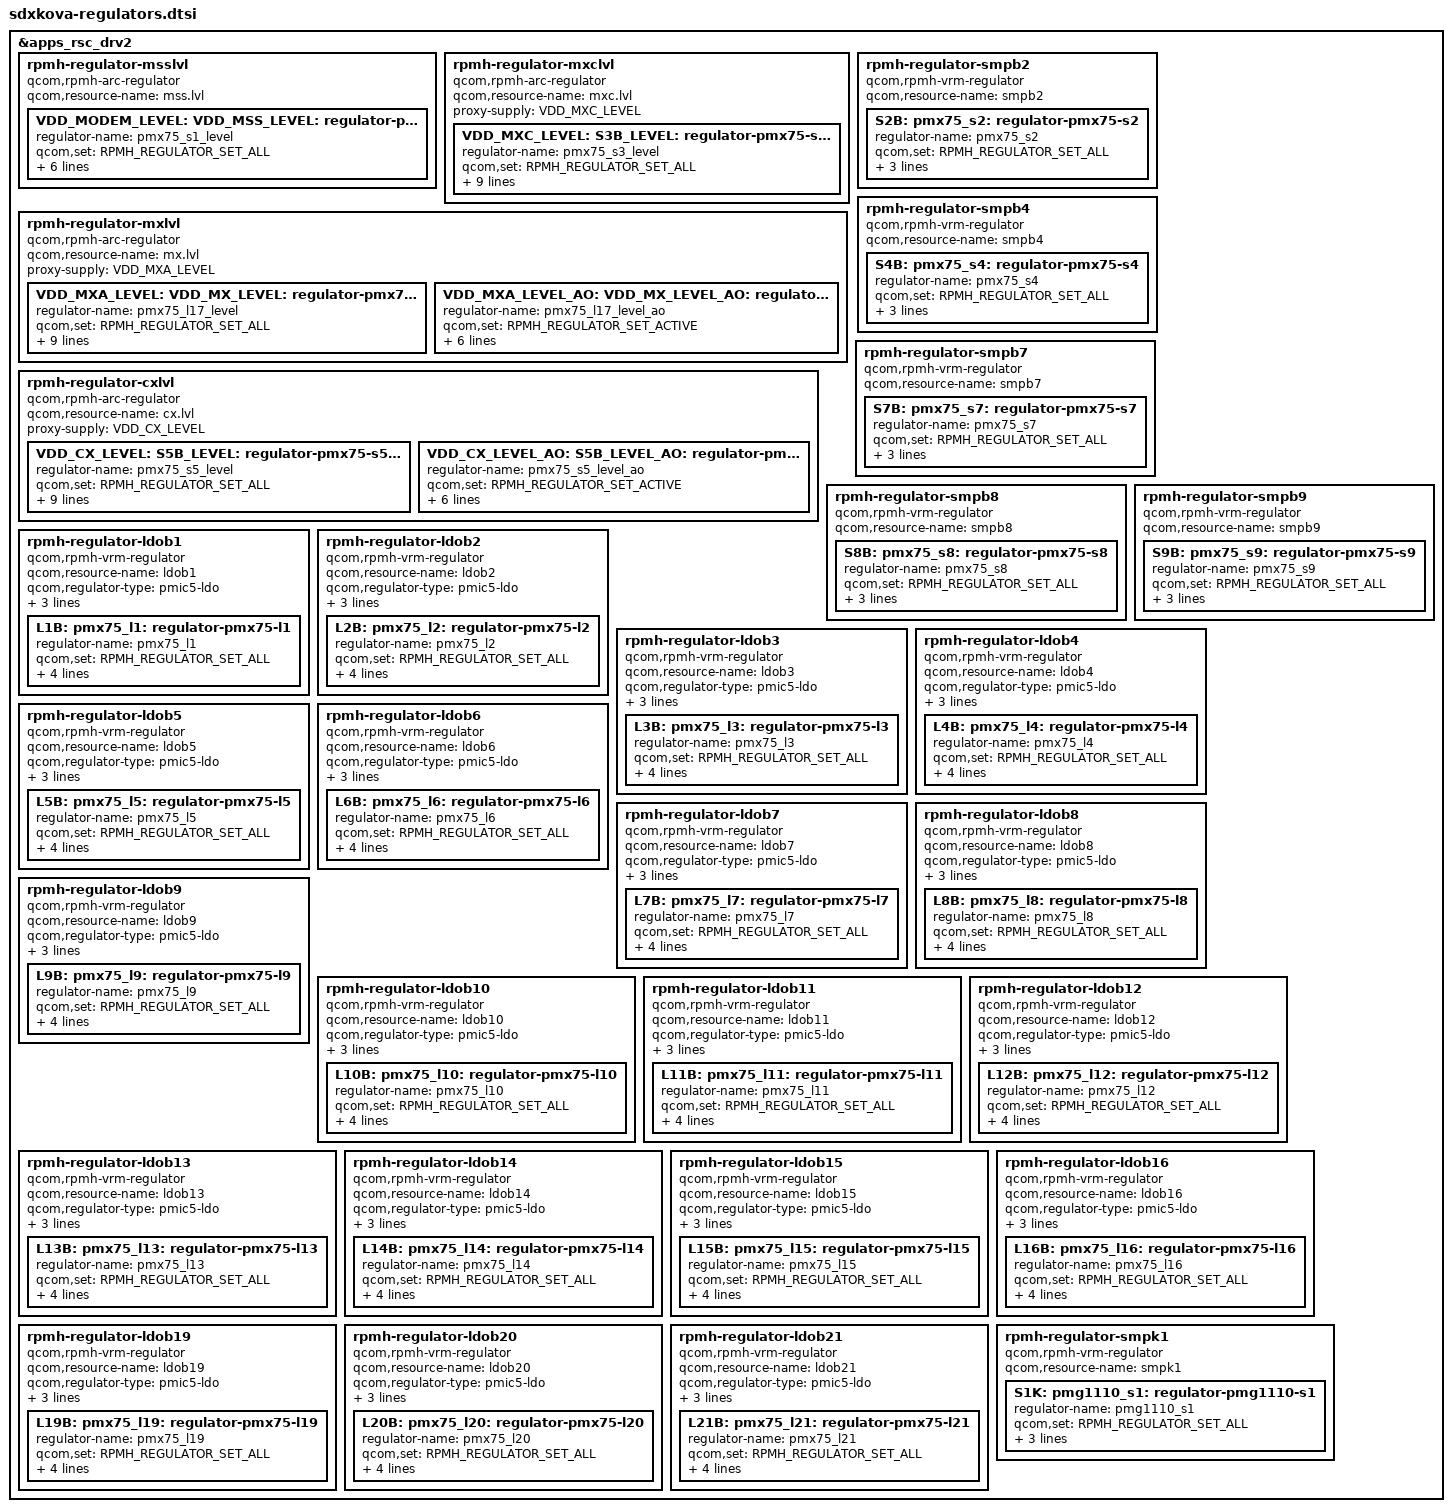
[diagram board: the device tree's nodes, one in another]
// SPDX-License-Identifier: BSD-3-Clause
/*
 * Copyright (c) 2024 Qualcomm Innovation Center, Inc. All rights reserved.
 */

#include <dt-bindings/regulator/qcom,rpmh-regulator-levels.h>

&apps_rsc_drv2 {
	rpmh-regulator-msslvl {
		compatible = "qcom,rpmh-arc-regulator";
		qcom,resource-name = "mss.lvl";

		VDD_MODEM_LEVEL: VDD_MSS_LEVEL: S1B_LEVEL:
		pmx75_s1_level: regulator-pmx75-s1-level {
			regulator-name = "pmx75_s1_level";
			qcom,set = <RPMH_REGULATOR_SET_ALL>;
			regulator-min-microvolt =
				<RPMH_REGULATOR_LEVEL_RETENTION>;
			regulator-max-microvolt =
				<RPMH_REGULATOR_LEVEL_MAX>;
			qcom,init-voltage-level =
				<RPMH_REGULATOR_LEVEL_RETENTION>;
		};
	};

	rpmh-regulator-mxclvl {
		compatible = "qcom,rpmh-arc-regulator";
		qcom,resource-name = "mxc.lvl";
		proxy-supply = <&VDD_MXC_LEVEL>;

		VDD_MXC_LEVEL: S3B_LEVEL:
		pmx75_s3_level: regulator-pmx75-s3-level {
			regulator-name = "pmx75_s3_level";
			qcom,set = <RPMH_REGULATOR_SET_ALL>;
			regulator-min-microvolt =
				<RPMH_REGULATOR_LEVEL_RETENTION>;
			regulator-max-microvolt =
				<RPMH_REGULATOR_LEVEL_MAX>;
			qcom,init-voltage-level =
				<RPMH_REGULATOR_LEVEL_TURBO>;
			qcom,proxy-consumer-enable;
			qcom,proxy-consumer-voltage =
				<RPMH_REGULATOR_LEVEL_TURBO
				RPMH_REGULATOR_LEVEL_MAX>;
		};
	};

	rpmh-regulator-mxlvl {
		compatible = "qcom,rpmh-arc-regulator";
		qcom,resource-name = "mx.lvl";
		proxy-supply = <&VDD_MXA_LEVEL>;

		VDD_MXA_LEVEL: VDD_MX_LEVEL: L17B_LEVEL:
		pmx75_l17_level: regulator-pmx75-l17-level {
			regulator-name = "pmx75_l17_level";
			qcom,set = <RPMH_REGULATOR_SET_ALL>;
			regulator-min-microvolt =
				<RPMH_REGULATOR_LEVEL_RETENTION>;
			regulator-max-microvolt =
				<RPMH_REGULATOR_LEVEL_MAX>;
			qcom,init-voltage-level =
				<RPMH_REGULATOR_LEVEL_TURBO>;
			qcom,proxy-consumer-enable;
			qcom,proxy-consumer-voltage =
				<RPMH_REGULATOR_LEVEL_TURBO
				RPMH_REGULATOR_LEVEL_MAX>;
		};

		VDD_MXA_LEVEL_AO: VDD_MX_LEVEL_AO: L17B_LEVEL_AO:
		pmx75_l17_level_ao: regulator-pmx75-l17-level-ao {
			regulator-name = "pmx75_l17_level_ao";
			qcom,set = <RPMH_REGULATOR_SET_ACTIVE>;
			regulator-min-microvolt =
				<RPMH_REGULATOR_LEVEL_RETENTION>;
			regulator-max-microvolt =
				<RPMH_REGULATOR_LEVEL_MAX>;
			qcom,init-voltage-level =
				<RPMH_REGULATOR_LEVEL_RETENTION>;
		};
	};

	rpmh-regulator-cxlvl {
		compatible = "qcom,rpmh-arc-regulator";
		qcom,resource-name = "cx.lvl";
		proxy-supply = <&VDD_CX_LEVEL>;

		VDD_CX_LEVEL: S5B_LEVEL:
		pmx75_s5_level: regulator-pmx75-s5-level {
			regulator-name = "pmx75_s5_level";
			qcom,set = <RPMH_REGULATOR_SET_ALL>;
			regulator-min-microvolt =
				<RPMH_REGULATOR_LEVEL_RETENTION>;
			regulator-max-microvolt =
				<RPMH_REGULATOR_LEVEL_MAX>;
			qcom,init-voltage-level =
				<RPMH_REGULATOR_LEVEL_TURBO>;
			qcom,proxy-consumer-enable;
			qcom,proxy-consumer-voltage =
				<RPMH_REGULATOR_LEVEL_TURBO
				 RPMH_REGULATOR_LEVEL_MAX>;
		};

		VDD_CX_LEVEL_AO: S5B_LEVEL_AO:
		pmx75_s5_level_ao: regulator-pmx75-s5-level-ao {
			regulator-name = "pmx75_s5_level_ao";
			qcom,set = <RPMH_REGULATOR_SET_ACTIVE>;
			regulator-min-microvolt =
				<RPMH_REGULATOR_LEVEL_RETENTION>;
			regulator-max-microvolt =
				<RPMH_REGULATOR_LEVEL_MAX>;
			qcom,init-voltage-level =
				<RPMH_REGULATOR_LEVEL_RETENTION>;
		};
	};

	rpmh-regulator-smpb2 {
		compatible = "qcom,rpmh-vrm-regulator";
		qcom,resource-name = "smpb2";

		S2B: pmx75_s2: regulator-pmx75-s2 {
			regulator-name = "pmx75_s2";
			qcom,set = <RPMH_REGULATOR_SET_ALL>;
			regulator-min-microvolt = <1224000>;
			regulator-max-microvolt = <1350000>;
			qcom,init-voltage = <1224000>;
		};
	};

	rpmh-regulator-smpb4 {
		compatible = "qcom,rpmh-vrm-regulator";
		qcom,resource-name = "smpb4";

		S4B: pmx75_s4: regulator-pmx75-s4 {
			regulator-name = "pmx75_s4";
			qcom,set = <RPMH_REGULATOR_SET_ALL>;
			regulator-min-microvolt = <1824000>;
			regulator-max-microvolt = <1904000>;
			qcom,init-voltage = <1824000>;
		};
	};

	rpmh-regulator-smpb7 {
		compatible = "qcom,rpmh-vrm-regulator";
		qcom,resource-name = "smpb7";

		S7B: pmx75_s7: regulator-pmx75-s7 {
			regulator-name = "pmx75_s7";
			qcom,set = <RPMH_REGULATOR_SET_ALL>;
			regulator-min-microvolt = <352000>;
			regulator-max-microvolt = <1060000>;
			qcom,init-voltage = <936000>;
		};
	};

	rpmh-regulator-smpb8 {
		compatible = "qcom,rpmh-vrm-regulator";
		qcom,resource-name = "smpb8";

		S8B: pmx75_s8: regulator-pmx75-s8 {
			regulator-name = "pmx75_s8";
			qcom,set = <RPMH_REGULATOR_SET_ALL>;
			regulator-min-microvolt = <500000>;
			regulator-max-microvolt = <1100000>;
			qcom,init-voltage = <824000>;
		};
	};

	rpmh-regulator-smpb9 {
		compatible = "qcom,rpmh-vrm-regulator";
		qcom,resource-name = "smpb9";

		S9B: pmx75_s9: regulator-pmx75-s9 {
			regulator-name = "pmx75_s9";
			qcom,set = <RPMH_REGULATOR_SET_ALL>;
			regulator-min-microvolt = <300000>;
			regulator-max-microvolt = <1040000>;
			qcom,init-voltage = <800000>;
		};
	};

	rpmh-regulator-ldob1 {
		compatible = "qcom,rpmh-vrm-regulator";
		qcom,resource-name = "ldob1";
		qcom,regulator-type = "pmic5-ldo";
		qcom,supported-modes =
			<RPMH_REGULATOR_MODE_LPM
			 RPMH_REGULATOR_MODE_HPM>;
		qcom,mode-threshold-currents = <0 30000>;

		L1B: pmx75_l1: regulator-pmx75-l1 {
			regulator-name = "pmx75_l1";
			qcom,set = <RPMH_REGULATOR_SET_ALL>;
			regulator-min-microvolt = <1200000>;
			regulator-max-microvolt = <1200000>;
			qcom,init-voltage = <1200000>;
			qcom,init-mode = <RPMH_REGULATOR_MODE_HPM>;
		};
	};

	rpmh-regulator-ldob2 {
		compatible = "qcom,rpmh-vrm-regulator";
		qcom,resource-name = "ldob2";
		qcom,regulator-type = "pmic5-ldo";
		qcom,supported-modes =
			<RPMH_REGULATOR_MODE_LPM
			 RPMH_REGULATOR_MODE_HPM>;
		qcom,mode-threshold-currents = <0 30000>;

		L2B: pmx75_l2: regulator-pmx75-l2 {
			regulator-name = "pmx75_l2";
			qcom,set = <RPMH_REGULATOR_SET_ALL>;
			regulator-min-microvolt = <1000000>;
			regulator-max-microvolt = <1160000>;
			qcom,init-voltage = <1128000>;
			qcom,init-mode = <RPMH_REGULATOR_MODE_HPM>;
		};
	};

	rpmh-regulator-ldob3 {
		compatible = "qcom,rpmh-vrm-regulator";
		qcom,resource-name = "ldob3";
		qcom,regulator-type = "pmic5-ldo";
		qcom,supported-modes =
			<RPMH_REGULATOR_MODE_LPM
			 RPMH_REGULATOR_MODE_HPM>;
		qcom,mode-threshold-currents = <0 30000>;

		L3B: pmx75_l3: regulator-pmx75-l3 {
			regulator-name = "pmx75_l3";
			qcom,set = <RPMH_REGULATOR_SET_ALL>;
			regulator-min-microvolt = <300000>;
			regulator-max-microvolt = <1040000>;
			qcom,init-voltage = <896000>;
			qcom,init-mode = <RPMH_REGULATOR_MODE_HPM>;
		};
	};

	rpmh-regulator-ldob4 {
		compatible = "qcom,rpmh-vrm-regulator";
		qcom,resource-name = "ldob4";
		qcom,regulator-type = "pmic5-ldo";
		qcom,supported-modes =
			<RPMH_REGULATOR_MODE_LPM
			 RPMH_REGULATOR_MODE_HPM>;
		qcom,mode-threshold-currents = <0 30000>;

		L4B: pmx75_l4: regulator-pmx75-l4 {
			regulator-name = "pmx75_l4";
			qcom,set = <RPMH_REGULATOR_SET_ALL>;
			regulator-min-microvolt = <864000>;
			regulator-max-microvolt = <912000>;
			qcom,init-voltage = <880000>;
			qcom,init-mode = <RPMH_REGULATOR_MODE_HPM>;
		};
	};

	rpmh-regulator-ldob5 {
		compatible = "qcom,rpmh-vrm-regulator";
		qcom,resource-name = "ldob5";
		qcom,regulator-type = "pmic5-ldo";
		qcom,supported-modes =
			<RPMH_REGULATOR_MODE_LPM
			 RPMH_REGULATOR_MODE_HPM>;
		qcom,mode-threshold-currents = <0 10000>;

		L5B: pmx75_l5: regulator-pmx75-l5 {
			regulator-name = "pmx75_l5";
			qcom,set = <RPMH_REGULATOR_SET_ALL>;
			regulator-min-microvolt = <1770000>;
			regulator-max-microvolt = <1800000>;
			qcom,init-voltage = <1776000>;
			qcom,init-mode = <RPMH_REGULATOR_MODE_HPM>;
		};
	};

	rpmh-regulator-ldob6 {
		compatible = "qcom,rpmh-vrm-regulator";
		qcom,resource-name = "ldob6";
		qcom,regulator-type = "pmic5-ldo";
		qcom,supported-modes =
			<RPMH_REGULATOR_MODE_LPM
			 RPMH_REGULATOR_MODE_HPM>;
		qcom,mode-threshold-currents = <0 10000>;

		L6B: pmx75_l6: regulator-pmx75-l6 {
			regulator-name = "pmx75_l6";
			qcom,set = <RPMH_REGULATOR_SET_ALL>;
			regulator-min-microvolt = <1800000>;
			regulator-max-microvolt = <1800000>;
			qcom,init-voltage = <1800000>;
			qcom,init-mode = <RPMH_REGULATOR_MODE_HPM>;
		};
	};

	rpmh-regulator-ldob7 {
		compatible = "qcom,rpmh-vrm-regulator";
		qcom,resource-name = "ldob7";
		qcom,regulator-type = "pmic5-ldo";
		qcom,supported-modes =
			<RPMH_REGULATOR_MODE_LPM
			 RPMH_REGULATOR_MODE_HPM>;
		qcom,mode-threshold-currents = <0 30000>;

		L7B: pmx75_l7: regulator-pmx75-l7 {
			regulator-name = "pmx75_l7";
			qcom,set = <RPMH_REGULATOR_SET_ALL>;
			regulator-min-microvolt = <300000>;
			regulator-max-microvolt = <960000>;
			qcom,init-voltage = <904000>;
			qcom,init-mode = <RPMH_REGULATOR_MODE_HPM>;
		};
	};

	rpmh-regulator-ldob8 {
		compatible = "qcom,rpmh-vrm-regulator";
		qcom,resource-name = "ldob8";
		qcom,regulator-type = "pmic5-ldo";
		qcom,supported-modes =
			<RPMH_REGULATOR_MODE_LPM
			 RPMH_REGULATOR_MODE_HPM>;
		qcom,mode-threshold-currents = <0 30000>;

		L8B: pmx75_l8: regulator-pmx75-l8 {
			regulator-name = "pmx75_l8";
			qcom,set = <RPMH_REGULATOR_SET_ALL>;
			regulator-min-microvolt = <800000>;
			regulator-max-microvolt = <800000>;
			qcom,init-voltage = <800000>;
			qcom,init-mode = <RPMH_REGULATOR_MODE_HPM>;
		};
	};

	rpmh-regulator-ldob9 {
		compatible = "qcom,rpmh-vrm-regulator";
		qcom,resource-name = "ldob9";
		qcom,regulator-type = "pmic5-ldo";
		qcom,supported-modes =
			<RPMH_REGULATOR_MODE_LPM
			 RPMH_REGULATOR_MODE_HPM>;
		qcom,mode-threshold-currents = <0 30000>;

		L9B: pmx75_l9: regulator-pmx75-l9 {
			regulator-name = "pmx75_l9";
			qcom,set = <RPMH_REGULATOR_SET_ALL>;
			regulator-min-microvolt = <752000>;
			regulator-max-microvolt = <800000>;
			qcom,init-voltage = <752000>;
			qcom,init-mode = <RPMH_REGULATOR_MODE_HPM>;
		};
	};

	rpmh-regulator-ldob10 {
		compatible = "qcom,rpmh-vrm-regulator";
		qcom,resource-name = "ldob10";
		qcom,regulator-type = "pmic5-ldo";
		qcom,supported-modes =
			<RPMH_REGULATOR_MODE_LPM
			 RPMH_REGULATOR_MODE_HPM>;
		qcom,mode-threshold-currents = <0 10000>;

		L10B: pmx75_l10: regulator-pmx75-l10 {
			regulator-name = "pmx75_l10";
			qcom,set = <RPMH_REGULATOR_SET_ALL>;
			regulator-min-microvolt = <3008000>;
			regulator-max-microvolt = <3088000>;
			qcom,init-voltage = <3080000>;
			qcom,init-mode = <RPMH_REGULATOR_MODE_HPM>;
		};
	};

	rpmh-regulator-ldob11 {
		compatible = "qcom,rpmh-vrm-regulator";
		qcom,resource-name = "ldob11";
		qcom,regulator-type = "pmic5-ldo";
		qcom,supported-modes =
			<RPMH_REGULATOR_MODE_LPM
			 RPMH_REGULATOR_MODE_HPM>;
		qcom,mode-threshold-currents = <0 10000>;

		L11B: pmx75_l11: regulator-pmx75-l11 {
			regulator-name = "pmx75_l11";
			qcom,set = <RPMH_REGULATOR_SET_ALL>;
			regulator-min-microvolt = <1704000>;
			regulator-max-microvolt = <2928000>;
			qcom,init-voltage = <1800000>;
			qcom,init-mode = <RPMH_REGULATOR_MODE_HPM>;
		};
	};

	rpmh-regulator-ldob12 {
		compatible = "qcom,rpmh-vrm-regulator";
		qcom,resource-name = "ldob12";
		qcom,regulator-type = "pmic5-ldo";
		qcom,supported-modes =
			<RPMH_REGULATOR_MODE_LPM
			 RPMH_REGULATOR_MODE_HPM>;
		qcom,mode-threshold-currents = <0 30000>;

		L12B: pmx75_l12: regulator-pmx75-l12 {
			regulator-name = "pmx75_l12";
			qcom,set = <RPMH_REGULATOR_SET_ALL>;
			regulator-min-microvolt = <1200000>;
			regulator-max-microvolt = <1200000>;
			qcom,init-voltage = <1200000>;
			qcom,init-mode = <RPMH_REGULATOR_MODE_HPM>;
		};
	};

	rpmh-regulator-ldob13 {
		compatible = "qcom,rpmh-vrm-regulator";
		qcom,resource-name = "ldob13";
		qcom,regulator-type = "pmic5-ldo";
		qcom,supported-modes =
			<RPMH_REGULATOR_MODE_LPM
			 RPMH_REGULATOR_MODE_HPM>;
		qcom,mode-threshold-currents = <0 10000>;

		L13B: pmx75_l13: regulator-pmx75-l13 {
			regulator-name = "pmx75_l13";
			qcom,set = <RPMH_REGULATOR_SET_ALL>;
			regulator-min-microvolt = <1704000>;
			regulator-max-microvolt = <2928000>;
			qcom,init-voltage = <1800000>;
			qcom,init-mode = <RPMH_REGULATOR_MODE_HPM>;
		};
	};

	rpmh-regulator-ldob14 {
		compatible = "qcom,rpmh-vrm-regulator";
		qcom,resource-name = "ldob14";
		qcom,regulator-type = "pmic5-ldo";
		qcom,supported-modes =
			<RPMH_REGULATOR_MODE_LPM
			 RPMH_REGULATOR_MODE_HPM>;
		qcom,mode-threshold-currents = <0 30000>;

		L14B: pmx75_l14: regulator-pmx75-l14 {
			regulator-name = "pmx75_l14";
			qcom,set = <RPMH_REGULATOR_SET_ALL>;
			regulator-min-microvolt = <300000>;
			regulator-max-microvolt = <800000>;
			qcom,init-voltage = <624000>;
			qcom,init-mode = <RPMH_REGULATOR_MODE_HPM>;
		};
	};

	rpmh-regulator-ldob15 {
		compatible = "qcom,rpmh-vrm-regulator";
		qcom,resource-name = "ldob15";
		qcom,regulator-type = "pmic5-ldo";
		qcom,supported-modes =
			<RPMH_REGULATOR_MODE_LPM
			 RPMH_REGULATOR_MODE_HPM>;
		qcom,mode-threshold-currents = <0 30000>;

		L15B: pmx75_l15: regulator-pmx75-l15 {
			regulator-name = "pmx75_l15";
			qcom,set = <RPMH_REGULATOR_SET_ALL>;
			regulator-min-microvolt = <1200000>;
			regulator-max-microvolt = <1200000>;
			qcom,init-voltage = <1200000>;
			qcom,init-mode = <RPMH_REGULATOR_MODE_HPM>;
		};
	};

	rpmh-regulator-ldob16 {
		compatible = "qcom,rpmh-vrm-regulator";
		qcom,resource-name = "ldob16";
		qcom,regulator-type = "pmic5-ldo";
		qcom,supported-modes =
			<RPMH_REGULATOR_MODE_LPM
			 RPMH_REGULATOR_MODE_HPM>;
		qcom,mode-threshold-currents = <0 30000>;

		L16B: pmx75_l16: regulator-pmx75-l16 {
			regulator-name = "pmx75_l16";
			qcom,set = <RPMH_REGULATOR_SET_ALL>;
			regulator-min-microvolt = <880000>;
			regulator-max-microvolt = <920000>;
			qcom,init-voltage = <912000>;
			qcom,init-mode = <RPMH_REGULATOR_MODE_HPM>;
		};
	};

	rpmh-regulator-ldob19 {
		compatible = "qcom,rpmh-vrm-regulator";
		qcom,resource-name = "ldob19";
		qcom,regulator-type = "pmic5-ldo";
		qcom,supported-modes =
			<RPMH_REGULATOR_MODE_LPM
			 RPMH_REGULATOR_MODE_HPM>;
		qcom,mode-threshold-currents = <0 30000>;

		L19B: pmx75_l19: regulator-pmx75-l19 {
			regulator-name = "pmx75_l19";
			qcom,set = <RPMH_REGULATOR_SET_ALL>;
			regulator-min-microvolt = <900000>;
			regulator-max-microvolt = <960000>;
			qcom,init-voltage = <952000>;
			qcom,init-mode = <RPMH_REGULATOR_MODE_HPM>;
		};
	};

	rpmh-regulator-ldob20 {
		compatible = "qcom,rpmh-vrm-regulator";
		qcom,resource-name = "ldob20";
		qcom,regulator-type = "pmic5-ldo";
		qcom,supported-modes =
			<RPMH_REGULATOR_MODE_LPM
			 RPMH_REGULATOR_MODE_HPM>;
		qcom,mode-threshold-currents = <0 30000>;

		L20B: pmx75_l20: regulator-pmx75-l20 {
			regulator-name = "pmx75_l20";
			qcom,set = <RPMH_REGULATOR_SET_ALL>;
			regulator-min-microvolt = <912000>;
			regulator-max-microvolt = <952000>;
			qcom,init-voltage = <912000>;
			qcom,init-mode = <RPMH_REGULATOR_MODE_HPM>;
		};
	};

	rpmh-regulator-ldob21 {
		compatible = "qcom,rpmh-vrm-regulator";
		qcom,resource-name = "ldob21";
		qcom,regulator-type = "pmic5-ldo";
		qcom,supported-modes =
			<RPMH_REGULATOR_MODE_LPM
			 RPMH_REGULATOR_MODE_HPM>;
		qcom,mode-threshold-currents = <0 30000>;

		L21B: pmx75_l21: regulator-pmx75-l21 {
			regulator-name = "pmx75_l21";
			qcom,set = <RPMH_REGULATOR_SET_ALL>;
			regulator-min-microvolt = <300000>;
			regulator-max-microvolt = <1000000>;
			qcom,init-voltage = <856000>;
			qcom,init-mode = <RPMH_REGULATOR_MODE_HPM>;
		};
	};

	rpmh-regulator-smpk1 {
		compatible = "qcom,rpmh-vrm-regulator";
		qcom,resource-name = "smpk1";

		S1K: pmg1110_s1: regulator-pmg1110-s1 {
			regulator-name = "pmg1110_s1";
			qcom,set = <RPMH_REGULATOR_SET_ALL>;
			regulator-min-microvolt = <800000>;
			regulator-max-microvolt = <1000000>;
			qcom,init-voltage = <916000>;
		};
	};
};
